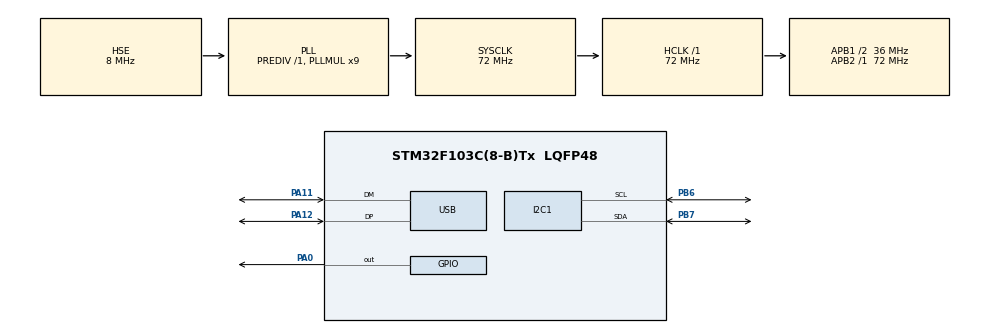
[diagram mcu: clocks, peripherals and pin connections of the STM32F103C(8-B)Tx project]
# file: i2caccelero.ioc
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Mcu.Family=STM32F1
Mcu.Name=STM32F103C(8-B)Tx
Mcu.Package=LQFP48
NVIC.PriorityGroup=NVIC_PRIORITYGROUP_4
NVIC.USB_LP_CAN1_RX0_IRQn=true\:0\:0\:false\:false\:true\:false\:true\:true
PA0-WKUP.Signal=GPIO_Output
PA11.Mode=Device
PA11.Signal=USB_DM
PA12.Mode=Device
PA12.Signal=USB_DP
PA13.Mode=Serial_Wire
PA13.Signal=SYS_JTMS-SWDIO
PA14.Mode=Serial_Wire
PA14.Signal=SYS_JTCK-SWCLK
PB6.Mode=I2C
PB6.Signal=I2C1_SCL
PB7.Mode=I2C
PB7.Signal=I2C1_SDA
PD0-OSC_IN.Mode=HSE-External-Oscillator
PD0-OSC_IN.Signal=RCC_OSC_IN
PD1-OSC_OUT.Mode=HSE-External-Oscillator
PD1-OSC_OUT.Signal=RCC_OSC_OUT
ProjectManager.HeapSize=0x200
ProjectManager.StackSize=0x400
ProjectManager.TargetToolchain=STM32CubeIDE
RCC.AHBFreq_Value=72000000
RCC.APB1CLKDivider=RCC_HCLK_DIV2
RCC.APB1Freq_Value=36000000
RCC.APB1TimFreq_Value=72000000
RCC.APB2Freq_Value=72000000
RCC.APB2TimFreq_Value=72000000
RCC.HCLKFreq_Value=72000000
RCC.PLLMUL=RCC_PLL_MUL9
RCC.PLLSourceVirtual=RCC_PLLSOURCE_HSE
RCC.SYSCLKFreq_VALUE=72000000
RCC.SYSCLKSource=RCC_SYSCLKSOURCE_PLLCLK
RCC.USBFreq_Value=48000000
RCC.USBPrescaler=RCC_USBCLKSOURCE_PLL_DIV1_5
USB_DEVICE.CLASS_NAME_FS=CDC
USB_DEVICE.VirtualMode=Cdc
USB_DEVICE.VirtualModeFS=Cdc_FS
VP_USB_DEVICE_VS_USB_DEVICE_CDC_FS.Mode=CDC_FS
board=custom

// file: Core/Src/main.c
/* USER CODE BEGIN Header */
/**
  ******************************************************************************
  * @file           : main.c
  * @brief          : Main program body
  ******************************************************************************
  * @attention
  *
  * Copyright (c) 2025 STMicroelectronics.
  * All rights reserved.
  *
  * This software is licensed under terms that can be found in the LICENSE file
  * in the root directory of this software component.
  * If no LICENSE file comes with this software, it is provided AS-IS.
  *
  ******************************************************************************
  */
/* USER CODE END Header */
#include "main.h"
#include "usb_device.h"

/* USER CODE BEGIN Includes */
#include "usbd_cdc_if.h"
#include "string.h"
#include <stdio.h>
#include "FIR_Filter.h"

// Define the ADXL345 I2C address
#define ADXL345_ADDR 0x53 << 1 // Shifted for STM32 HAL I2C

#define FILTER_ORDER 8  // Choose an appropriate order
float fir_coeff[FILTER_ORDER] = {0.25f, 0.25f, 0.25f, 0.25f,0.25f, 0.25f, 0.25f, 0.25f};  // Moving average coefficients
float fir_buffer[FILTER_ORDER];  // Buffer for FIR filter
FIRFilter x_filter;  // FIR filter instance

/* USER CODE END Includes */

I2C_HandleTypeDef hi2c1;

void SystemClock_Config(void);
static void MX_GPIO_Init(void);
static void MX_I2C1_Init(void);

/* USER CODE BEGIN 0 */
int16_t X_out, Y_out, Z_out;
char buffer[100];

void ADXL345_Init(void);
void ADXL345_ReadData(void);

//void setup_filter() {
 //   FIRFilter_Init(&fir_filter, fir_coeff, fir_buffer, FIR_ORDER);
//}

/* USER CODE END 0 */

int main(void)
{

  /* MCU Configuration--------------------------------------------------------*/

  /* Reset of all peripherals, Initializes the Flash interface and the Systick. */
  HAL_Init();

  /* Configure the system clock */
  SystemClock_Config();

  /* Initialize all configured peripherals */
  MX_GPIO_Init();
  MX_I2C1_Init();
  MX_USB_DEVICE_Init();
  /* USER CODE BEGIN 2 */
  FIRFilter_Init(&x_filter, fir_coeff, fir_buffer, FILTER_ORDER);
  /* USER CODE END 2 */

  /* Infinite loop */
  while (1)
  {
	    ADXL345_Init(); // Initialize ADXL345

	    while (1)
	    {
	        ADXL345_ReadData();
	       // snprintf(buffer, sizeof(buffer), "Xa= %.2f   Ya= %.2f   Za= %.2f\r\n", X_out / 256.0, Y_out / 256.0, Z_out / 256.0);
	       // HAL_UART_Transmit(&huart2, (uint8_t *)buffer, strlen(buffer), HAL_MAX_DELAY);
	        //CDC_Transmit_FS((uint8_t *)buffer, strlen(buffer));
	        CDC_Transmit_FS((uint8_t *)buffer, strlen(buffer));
	        HAL_Delay(50); // Delay to control the output rate
	    }
  }
}

void ADXL345_Init(void)
{
    uint8_t data[2];

    // Set POWER_CTL register (0x2D) to enable measurement (bit D3)
    data[0] = 0x2D; // POWER_CTL register
    data[1] = 0x08; // Measurement mode
    HAL_I2C_Master_Transmit(&hi2c1, ADXL345_ADDR, data, 2, HAL_MAX_DELAY);
}
float x_filtered;

void ADXL345_ReadData(void) {
    uint8_t data[6];
    int16_t rawX, rawY, rawZ;

    uint8_t reg = 0x32;
    HAL_I2C_Master_Transmit(&hi2c1, ADXL345_ADDR, &reg, 1, HAL_MAX_DELAY);
    HAL_I2C_Master_Receive(&hi2c1, ADXL345_ADDR, data, 6, HAL_MAX_DELAY);

    rawX = ((int16_t)data[1] << 8) | data[0];
    rawY = ((int16_t)data[3] << 8) | data[2];
    rawZ = ((int16_t)data[5] << 8) | data[4];

    X_out = rawX;
    Y_out = rawY;
    Z_out = rawZ;

    // Apply FIR filter to X-axis data
    x_filtered = FIRFilter_Update(&x_filter, (float)X_out);

    // Update buffer to include filtered X value
    //snprintf(buffer, sizeof(buffer), "Xa= %.2f (Filtered= %.2f) Ya= %.2f Za= %.2f\r\n",
        //     X_out / 256.0, x_filtered / 256.0, Y_out / 256.0, Z_out / 256.0);
    snprintf(buffer, sizeof(buffer), "Xa= %.2f (Filtered= %.2f)\r\n", X_out / 256.0, x_filtered / 256.0);

}

void SystemClock_Config(void)
{
  RCC_OscInitTypeDef RCC_OscInitStruct = {0};
  RCC_ClkInitTypeDef RCC_ClkInitStruct = {0};
  RCC_PeriphCLKInitTypeDef PeriphClkInit = {0};

  /** Initializes the RCC Oscillators according to the specified parameters
  * in the RCC_OscInitTypeDef structure.
  */
  RCC_OscInitStruct.OscillatorType = RCC_OSCILLATORTYPE_HSE;
  RCC_OscInitStruct.HSEState = RCC_HSE_ON;
  RCC_OscInitStruct.HSEPredivValue = RCC_HSE_PREDIV_DIV1;
  RCC_OscInitStruct.HSIState = RCC_HSI_ON;
  RCC_OscInitStruct.PLL.PLLState = RCC_PLL_ON;
  RCC_OscInitStruct.PLL.PLLSource = RCC_PLLSOURCE_HSE;
  RCC_OscInitStruct.PLL.PLLMUL = RCC_PLL_MUL9;
  if (HAL_RCC_OscConfig(&RCC_OscInitStruct) != HAL_OK)
  {
    Error_Handler();
  }

  /** Initializes the CPU, AHB and APB buses clocks
  */
  RCC_ClkInitStruct.ClockType = RCC_CLOCKTYPE_HCLK|RCC_CLOCKTYPE_SYSCLK
                              |RCC_CLOCKTYPE_PCLK1|RCC_CLOCKTYPE_PCLK2;
  RCC_ClkInitStruct.SYSCLKSource = RCC_SYSCLKSOURCE_PLLCLK;
  RCC_ClkInitStruct.AHBCLKDivider = RCC_SYSCLK_DIV1;
  RCC_ClkInitStruct.APB1CLKDivider = RCC_HCLK_DIV2;
  RCC_ClkInitStruct.APB2CLKDivider = RCC_HCLK_DIV1;

  if (HAL_RCC_ClockConfig(&RCC_ClkInitStruct, FLASH_LATENCY_2) != HAL_OK)
  {
    Error_Handler();
  }
  PeriphClkInit.PeriphClockSelection = RCC_PERIPHCLK_USB;
  PeriphClkInit.UsbClockSelection = RCC_USBCLKSOURCE_PLL_DIV1_5;
  if (HAL_RCCEx_PeriphCLKConfig(&PeriphClkInit) != HAL_OK)
  {
    Error_Handler();
  }
}

static void MX_I2C1_Init(void)
{

  hi2c1.Instance = I2C1;
  hi2c1.Init.ClockSpeed = 100000;
  hi2c1.Init.DutyCycle = I2C_DUTYCYCLE_2;
  hi2c1.Init.OwnAddress1 = 0;
  hi2c1.Init.AddressingMode = I2C_ADDRESSINGMODE_7BIT;
  hi2c1.Init.DualAddressMode = I2C_DUALADDRESS_DISABLE;
  hi2c1.Init.OwnAddress2 = 0;
  hi2c1.Init.GeneralCallMode = I2C_GENERALCALL_DISABLE;
  hi2c1.Init.NoStretchMode = I2C_NOSTRETCH_DISABLE;
  if (HAL_I2C_Init(&hi2c1) != HAL_OK)
  {
    Error_Handler();
  }

}

static void MX_GPIO_Init(void)
{
  GPIO_InitTypeDef GPIO_InitStruct = {0};

  /* GPIO Ports Clock Enable */
  __HAL_RCC_GPIOD_CLK_ENABLE();
  __HAL_RCC_GPIOA_CLK_ENABLE();
  __HAL_RCC_GPIOB_CLK_ENABLE();

  /*Configure GPIO pin Output Level */
  HAL_GPIO_WritePin(GPIOA, GPIO_PIN_0, GPIO_PIN_RESET);

  /*Configure GPIO pin : PA0 */
  GPIO_InitStruct.Pin = GPIO_PIN_0;
  GPIO_InitStruct.Mode = GPIO_MODE_OUTPUT_PP;
  GPIO_InitStruct.Pull = GPIO_NOPULL;
  GPIO_InitStruct.Speed = GPIO_SPEED_FREQ_LOW;
  HAL_GPIO_Init(GPIOA, &GPIO_InitStruct);

}

void Error_Handler(void)
{
  __disable_irq();
  while (1)
  {
  }
}
